# STM32H503 register map
File version: 0.3
CPU: CM33 r0p0, little endian, MPU, FPU, 4 interrupt priority bits
Registers are 32-bit, read-write, reset 0x0 unless marked. A register's access mark holds for its fields unless they carry their own. Offsets are from the block's base; [hi:lo] are bit positions; {n}, {i} and the like mark numbered series.

## EXTI — Extended interrupt/event controller
Base 0x44022000
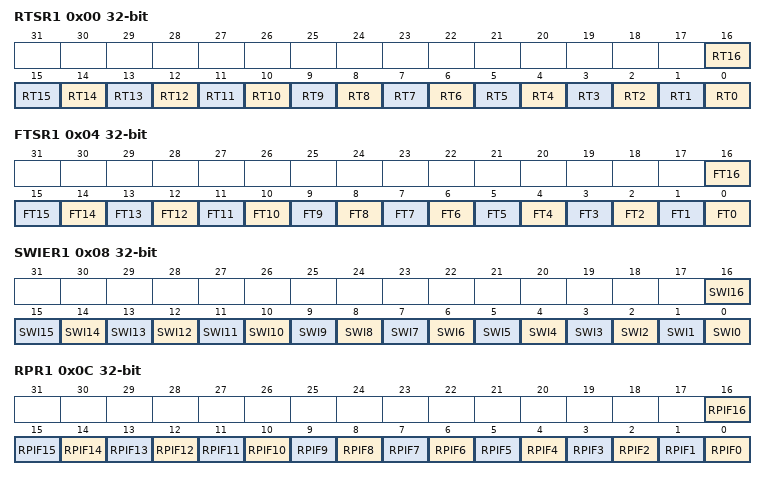
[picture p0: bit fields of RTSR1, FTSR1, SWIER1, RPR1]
0x00 RTSR1 — EXTI rising trigger selection register
  [n] RT{n} (n=0..16) — Rising trigger event configuration bit of configurable event input x (x = 16 to 0) When EXTI_PRIVCFGR.PRIVx is disabled, RTx can be accessed with unprivileged and privileged access. When EXTI_PRIVCFGR.PRIVx is enabled, RTx can only be accessed with privileged access. Unprivileged write to this bit x is discarded, unprivileged read returns 0.
0x04 FTSR1 — EXTI falling trigger selection register
  [n] FT{n} (n=0..16) — Falling trigger event configuration bit of configurable event input x (x = 16 to 0) When EXTI_PRIVCFGR.PRIVx is disabled, FTx can be accessed with unprivileged and privileged access. When EXTI_PRIVCFGR.PRIVx is enabled, FTx can only be accessed with privileged access. Unprivileged write to this FTx is discarded, unprivileged read returns 0.
0x08 SWIER1 — EXTI software interrupt event register
  [n] SWI{n} (n=0..16) — Software interrupt on event x (x = 16 to 0) When EXTI_PRIVCFGR.PRIVx is disabled, SWIx can be accessed with unprivileged and privileged access. When EXTI_PRIVCFGR.PRIVx is enabled, SWIx can only be accessed with privileged access. Unprivileged write to this SWIx is discarded, unprivileged read returns 0. A software interrupt is generated independent from the setting in EXTI_RTSR and EXTI_FTSR. It always returns 0 when read.
0x0C RPR1 — EXTI rising edge pending register
  [n] RPIF{n} (n=0..16) — configurable event inputs x rising edge pending bit (x = 16 to 0) When EXTI_PRIVCFGR.PRIVx is disabled, RPIFx can be accessed with unprivileged and privileged access. When EXTI_PRIVCFGR.PRIVx is enabled, RPIFx can only be accessed with privileged access. Unprivileged write to this RPIFx is discarded, unprivileged read returns 0. This bit is set when the rising edge event or an EXTI_SWIER software trigger arrives on the configurable event line. This bit is cleared by writing 1 to it.
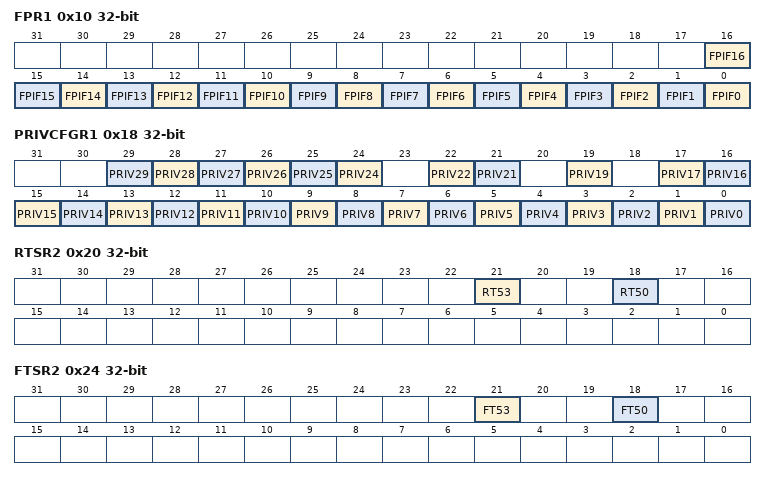
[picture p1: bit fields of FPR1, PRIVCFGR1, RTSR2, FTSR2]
0x10 FPR1 — EXTI falling edge pending register
  [n] FPIF{n} (n=0..16) — configurable event inputs x falling edge pending bit (x = 16 to 0) When EXTI_PRIVCFGR.PRIVx is disabled, FPIFx can be accessed with unprivileged and privileged access. When EXTI_PRIVCFGR.PRIVx is enabled, FPIFx can only be accessed with privileged access. Unprivileged write to this FPIFx is discarded, unprivileged read returns 0. This bit is set when the falling edge event arrives on the configurable event line. This bit is cleared by writing 1 to it.
0x18 PRIVCFGR1 — EXTI privilege configuration register
  [n] PRIV{n} (n=24..29) — Privilege enable on event input x (x = 29 to 24)
  [22] PRIV22 — Privilege enable on event input x (x = 22 to 21)
  [21] PRIV21 — Privilege enable on event input x (x = 22 to 21)
  [19] PRIV19 — Privilege enable on event input 19
  [n] PRIV{n} (n=0..17) — Privilege enable on event input x (x = 17 to 0)
0x20 RTSR2 — EXTI rising trigger selection register 2
  [21] RT53 — Rising trigger event configuration bit of configurable event input x When EXTI_PRIVCFGR.PRIVx is disabled, RTx can be accessed with unprivileged and privileged access. When EXTI_PRIVCFGR.PRIVx is enabled, RTx can only be accessed with privileged access. Unprivileged write to this bit x is discarded, unprivileged read returns 0.
  [18] RT50 — Rising trigger event configuration bit of configurable event input x When EXTI_PRIVCFGR.PRIVx is disabled, RTx can be accessed with unprivileged and privileged access. When EXTI_PRIVCFGR.PRIVx is enabled, RTx can only be accessed with privileged access. Unprivileged write to this bit x is discarded, unprivileged read returns 0.
0x24 FTSR2 — EXTI falling trigger selection register 2
  [21] FT53 — Falling trigger event configuration bit of configurable event input x When EXTI_PRIVCFGR.PRIVx is disabled, FTx can be accessed with unprivileged and privileged access. When EXTI_PRIVCFGR.PRIVx is enabled, FTx can only be accessed with privileged access. Unprivileged write to this FTx is discarded, unprivileged read returns 0.
  [18] FT50 — Falling trigger event configuration bit of configurable event input x When EXTI_PRIVCFGR.PRIVx is disabled, FTx can be accessed with unprivileged and privileged access. When EXTI_PRIVCFGR.PRIVx is enabled, FTx can only be accessed with privileged access. Unprivileged write to this FTx is discarded, unprivileged read returns 0.
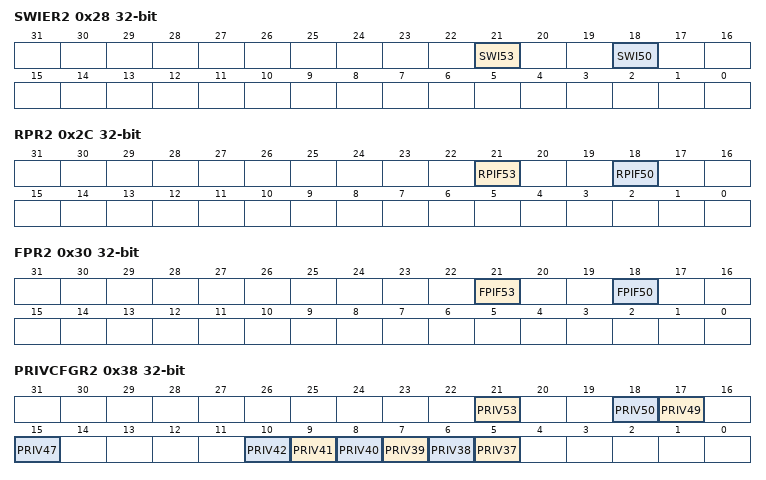
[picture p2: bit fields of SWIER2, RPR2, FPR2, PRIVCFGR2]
0x28 SWIER2 — EXTI software interrupt event register 2
  [21] SWI53 — Software interrupt on event x When EXTI_PRIVCFGR.PRIVx is disabled, SWIx can be accessed with unprivileged and privileged access. When EXTI_PRIVCFGR.PRIVx is enabled, SWIx can only be accessed with privileged access. Unprivileged write to this SWIx is discarded, unprivileged read returns 0. A software interrupt is generated independent from the setting in EXTI_RTSR and EXTI_FTSR. It always returns 0 when read.
  [18] SWI50 — Software interrupt on event x When EXTI_PRIVCFGR.PRIVx is disabled, SWIx can be accessed with unprivileged and privileged access. When EXTI_PRIVCFGR.PRIVx is enabled, SWIx can only be accessed with privileged access. Unprivileged write to this SWIx is discarded, unprivileged read returns 0. A software interrupt is generated independent from the setting in EXTI_RTSR and EXTI_FTSR. It always returns 0 when read.
0x2C RPR2 — EXTI rising edge pending register 2
  [21] RPIF53 — configurable event inputs x rising edge pending bit When EXTI_PRIVCFGR.PRIVx is disabled, RPIFx can be accessed with unprivileged and privileged access. When EXTI_PRIVCFGR.PRIVx is enabled, RPIFx can only be accessed with privileged access. Unprivileged write to this RPIFx is discarded, unprivileged read returns 0. This bit is set when the rising edge event or an EXTI_SWIER software trigger arrives on the configurable event line. This bit is cleared by writing 1 to it.
  [18] RPIF50 — configurable event inputs x rising edge pending bit When EXTI_PRIVCFGR.PRIVx is disabled, RPIFx can be accessed with unprivileged and privileged access. When EXTI_PRIVCFGR.PRIVx is enabled, RPIFx can only be accessed with privileged access. Unprivileged write to this RPIFx is discarded, unprivileged read returns 0. This bit is set when the rising edge event or an EXTI_SWIER software trigger arrives on the configurable event line. This bit is cleared by writing 1 to it.
0x30 FPR2 — EXTI falling edge pending register 2
  [21] FPIF53 — configurable event inputs x falling edge pending bit When EXTI_PRIVCFGR.PRIVx is disabled, FPIFx can be accessed with unprivileged and privileged access. When EXTI_PRIVCFGR.PRIVx is enabled, FPIFx can only be accessed with privileged access. Unprivileged write to this FPIFx is discarded, unprivileged read returns 0. This bit is set when the falling edge event arrives on the configurable event line. This bit is cleared by writing 1 to it.
  [18] FPIF50 — configurable event inputs x falling edge pending bit When EXTI_PRIVCFGR.PRIVx is disabled, FPIFx can be accessed with unprivileged and privileged access. When EXTI_PRIVCFGR.PRIVx is enabled, FPIFx can only be accessed with privileged access. Unprivileged write to this FPIFx is discarded, unprivileged read returns 0. This bit is set when the falling edge event arrives on the configurable event line. This bit is cleared by writing 1 to it.
0x38 PRIVCFGR2 — EXTI privilege configuration register 2
  [21] PRIV53 — Privilege enable on event input x
  [18] PRIV50 — Privilege enable on event input x (x = 50 to 49)
  [17] PRIV49 — Privilege enable on event input x (x = 50 to 49)
  [15] PRIV47 — Privilege enable on event input x
  [n-32] PRIV{n} (n=37..42) — Privilege enable on event input x (x = 42 to 37)
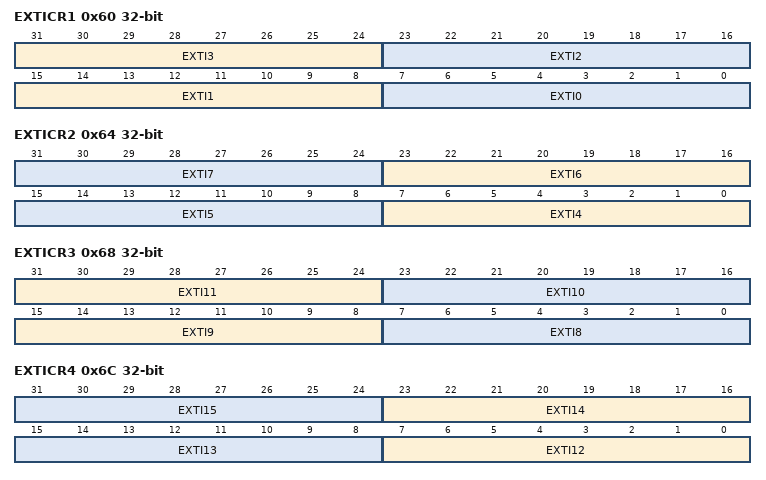
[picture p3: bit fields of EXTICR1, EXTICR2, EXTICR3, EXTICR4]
0x60 EXTICR1 — EXTI external interrupt selection register
  [31:24] EXTI3 — EXTI3 GPIO port selectio These bits are written by software to select the source input for EXTI3 external interrupt. When EXTI_PRIVCFGR.PRIV3 is disabled, EXTI3 can be accessed with privileged and unprivileged access. When EXTI_PRIVCFGR.PRIV3 is enabled, EXTI3 can only be accessed with privileged access. Unprivileged write to this bit is discarded. Others: reserved
  [23:16] EXTI2 — EXTI2 GPIO port selection These bits are written by software to select the source input for EXTI2 external interrupt. When EXTI_PRIVCFGR.PRIV2 is disabled, EXTI2 can be accessed with privileged and unprivileged access. When EXTI_PRIVCFGR.PRIV2 is enabled, EXTI2 can only be accessed with privileged access. Unprivileged write to this bit is discarded. Others: reserved
  [15:8] EXTI1 — EXTI1 GPIO port selection These bits are written by software to select the source input for EXTI1 external interrupt. When EXTI_PRIVCFGR.PRIV1 is disabled, EXTI1 can be accessed with privileged and unprivileged access. When EXTI_PRIVCFGR.PRIV1 is enabled, EXTI1 can only be accessed with privileged access. Unprivileged write to this bit is discarded. Others: reserved
  [7:0] EXTI0 — EXTI0 GPIO port selection These bits are written by software to select the source input for EXTI0 external interrupt. When EXTI_PRIVCFGR.PRIV0 is disabled, EXTI0 can be accessed with privileged and unprivileged access. When EXTI_PRIVCFGR.PRIV0 is enabled, EXTI0 can only be accessed with privileged access. Unprivileged write to this bit is discarded. Others: reserved
0x64 EXTICR2 — EXTI external interrupt selection register
  [8n-25:8n-32] EXTI{n} (n=4..7) — EXTI{n} GPIO port selection These bits are written by software to select the source input for EXTI{n} external interrupt. When EXTI_PRIVCFGR.PRIV{n} is disabled, EXTI{n} can be accessed with privileged and unprivileged access. When EXTI_PRIVCFGR.PRIV{n} is enabled, EXTI{n} can only be accessed with privileged access. Unprivileged write to this bit is discarded. Others: reserved
0x68 EXTICR3 — EXTI external interrupt selection register
  [31:24] EXTI11 — EXTI11 GPIO port selection These bits are written by software to select the source input for EXTI11 external interrupt. When EXTI_PRIVCFGR.PRIV11 is disabled, EXTI11 can be accessed with privileged and unprivileged access. When EXTI_PRIVCFGR.PRIV11 is enabled, EXTI11 can only be accessed with privileged access. Unprivileged write to this bit is discarded. Others: reserved
  [23:16] EXTI10 — EXTI10 GPIO port selection These bits are written by software to select the source input for EXTI10 external interrupt. When EXTI_PRIVCFGR.PRIV10 is disabled, EXTI10 can be accessed with privileged and unprivileged access. When EXTI_PRIVCFGR.PRIV10 is enabled, EXTI10 can only be accessed with privileged access. Unprivileged write to this bit is discarded. Others: reserved
  [15:8] EXTI9 — EXTI9 GPIO port selection These bits are written by software to select the source input for EXTI9 external interrupt. When EXTI_PRIVCFGR.PRIV9 is disabled, EXTI9 can be accessed with privileged and unprivileged access. When EXTI_PRIVCFGR.PRIV9 is enabled, EXTI9 can only be accessed with privileged access. Unprivileged write to this bit is discarded. Others: reserved
  [7:0] EXTI8 — EXTI8 GPIO port selection These bits are written by software to select the source input for EXTIm external interrupt. When EXTI_PRIVCFGR.PRIV8 is disabled, EXTI8 can be accessed with privileged and unprivileged access. When EXTI_PRIVCFGR.PRIV8 is enabled, EXTI8 can only be accessed with privileged access. Unprivileged write to this bit is discarded. Others: reserved
0x6C EXTICR4 — EXTI external interrupt selection register
  [8n-89:8n-96] EXTI{n} (n=12..15) — EXTI{n} GPIO port selection These bits are written by software to select the source input for EXTI{n} external interrupt. When EXTI_PRIVCFGR.PRIV{n} is disabled, EXTI{n} can be accessed with privileged and unprivileged access. When EXTI_PRIVCFGR.PRIV{n} is enabled, EXTI{n} can only be accessed with privileged access. Unprivileged write to this bit is discarded. Others: reserved
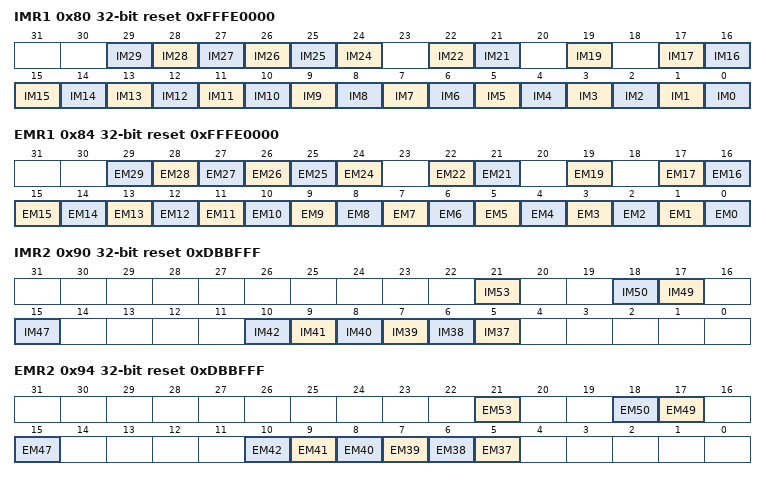
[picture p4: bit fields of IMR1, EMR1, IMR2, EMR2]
0x80 IMR1 reset 0xFFFE0000 — EXTI CPU wakeup with interrupt mask register
  [n] IM{n} (n=24..29) — CPU wakeup with interrupt mask on event input x (x = 29 to 24) When EXTI_PRIVCFGR.PRIVx is disabled, IMx can be accessed with privileged and unprivileged access. When EXTI_PRIVCFGR.PRIVx is enabled, IMx can only be accessed with privileged access. Unprivileged write to this bit is discarded.
  [22] IM22 — CPU wakeup with interrupt mask on event input x (x = 22 to 21) When EXTI_PRIVCFGR.PRIVx is disabled, IMx can be accessed with privileged and unprivileged access. When EXTI_PRIVCFGR.PRIVx is enabled, IMx can only be accessed with privileged access. Unprivileged write to this bit is discarded.
  [21] IM21 — CPU wakeup with interrupt mask on event input x (x = 22 to 21) When EXTI_PRIVCFGR.PRIVx is disabled, IMx can be accessed with privileged and unprivileged access. When EXTI_PRIVCFGR.PRIVx is enabled, IMx can only be accessed with privileged access. Unprivileged write to this bit is discarded.
  [19] IM19 — CPU wakeup with interrupt mask on event input x When EXTI_PRIVCFGR.PRIVx is disabled, IMx can be accessed with privileged and unprivileged access. When EXTI_PRIVCFGR.PRIVx is enabled, IMx can only be accessed with privileged access. Unprivileged write to this bit is discarded.
  [n] IM{n} (n=0..17) — CPU wakeup with interrupt mask on event input x (x = 17 to 0) When EXTI_PRIVCFGR.PRIVx is disabled, IMx can be accessed with privileged and unprivileged access. When EXTI_PRIVCFGR.PRIVx is enabled, IMx can only be accessed with privileged access. Unprivileged write to this bit is discarded.
0x84 EMR1 reset 0xFFFE0000 — EXTI CPU wakeup with event mask register
  [n] EM{n} (n=24..29) — CPU wakeup with event generation mask on event input x (x = 29 to 24) When EXTI_PRIVCFGR.PRIVx is disabled, EMx can be accessed with privileged and unprivileged access. When EXTI_PRIVCFGR.PRIVx is enabled, EMx can only be accessed with privileged access. Unprivileged write to this bit is discarded.
  [22] EM22 — CPU wakeup with event generation mask on event input x (x = 22 to 21) When EXTI_PRIVCFGR.PRIVx is disabled, EMx can be accessed with privileged and unprivileged access. When EXTI_PRIVCFGR.PRIVx is enabled, EMx can only be accessed with privileged access. Unprivileged write to this bit is discarded.
  [21] EM21 — CPU wakeup with event generation mask on event input x (x = 22 to 21) When EXTI_PRIVCFGR.PRIVx is disabled, EMx can be accessed with privileged and unprivileged access. When EXTI_PRIVCFGR.PRIVx is enabled, EMx can only be accessed with privileged access. Unprivileged write to this bit is discarded.
  [19] EM19 — CPU wakeup with event generation mask on event input x When EXTI_PRIVCFGR.PRIVx is disabled, EMx can be accessed with privileged and unprivileged access. When EXTI_PRIVCFGR.PRIVx is enabled, EMx can only be accessed with privileged access. Unprivileged write to this bit is discarded.
  [n] EM{n} (n=0..17) — CPU wakeup with event generation mask on event input x (x = 17 to 0) When EXTI_PRIVCFGR.PRIVx is disabled, EMx can be accessed with privileged and unprivileged access. When EXTI_PRIVCFGR.PRIVx is enabled, EMx can only be accessed with privileged access. Unprivileged write to this bit is discarded.
0x90 IMR2 reset 0xDBBFFF — EXTI CPU wakeup with interrupt mask register 2
  [21] IM53 — CPU wakeup with interrupt mask on event input x When EXTI_PRIVCFGR.PRIVx is disabled, IMx can be accessed with privileged and unprivileged access. When EXTI_PRIVCFGR.PRIVx is enabled, IMx can only be accessed with privileged access. Unprivileged write to this bit is discarded.
  [18] IM50 — CPU wakeup with interrupt mask on event input x (x = 50 to 49) When EXTI_PRIVCFGR.PRIVx is disabled, IMx can be accessed with privileged and unprivileged access. When EXTI_PRIVCFGR.PRIVx is enabled, IMx can only be accessed with privileged access. Unprivileged write to this bit is discarded.
  [17] IM49 — CPU wakeup with interrupt mask on event input x (x = 50 to 49) When EXTI_PRIVCFGR.PRIVx is disabled, IMx can be accessed with privileged and unprivileged access. When EXTI_PRIVCFGR.PRIVx is enabled, IMx can only be accessed with privileged access. Unprivileged write to this bit is discarded.
  [15] IM47 — CPU wakeup with interrupt mask on event input x When EXTI_PRIVCFGR.PRIVx is disabled, IMx can be accessed with privileged and unprivileged access. When EXTI_PRIVCFGR.PRIVx is enabled, IMx can only be accessed with privileged access. Unprivileged write to this bit is discarded.
  [n-32] IM{n} (n=37..42) — CPU wakeup with interrupt mask on event input x (x = 42 to 37) When EXTI_PRIVCFGR.PRIVx is disabled, IMx can be accessed with privileged and unprivileged access. When EXTI_PRIVCFGR.PRIVx is enabled, IMx can only be accessed with privileged access. Unprivileged write to this bit is discarded.
0x94 EMR2 reset 0xDBBFFF — EXTI CPU wakeup with event mask register 2
  [21] EM53 — CPU wakeup with event generation mask on event input x When EXTI_PRIVCFGR.PRIVx is disabled, EMx can be accessed with privileged and unprivileged access. When EXTI_PRIVCFGR.PRIVx is enabled, EMx can only be accessed with privileged access. Unprivileged write to this bit is discarded.
  [18] EM50 — CPU wakeup with event generation mask on event input x (x = 50 to 49) When EXTI_PRIVCFGR.PRIVx is disabled, EMx can be accessed with privileged and unprivileged access. When EXTI_PRIVCFGR.PRIVx is enabled, EMx can only be accessed with privileged access. Unprivileged write to this bit is discarded.
  [17] EM49 — CPU wakeup with event generation mask on event input x (x = 50 to 49) When EXTI_PRIVCFGR.PRIVx is disabled, EMx can be accessed with privileged and unprivileged access. When EXTI_PRIVCFGR.PRIVx is enabled, EMx can only be accessed with privileged access. Unprivileged write to this bit is discarded.
  [15] EM47 — CPU wakeup with event generation mask on event input x When EXTI_PRIVCFGR.PRIVx is disabled, EMx can be accessed with privileged and unprivileged access. When EXTI_PRIVCFGR.PRIVx is enabled, EMx can only be accessed with privileged access. Unprivileged write to this bit is discarded.
  [n-32] EM{n} (n=37..42) — CPU wakeup with event generation mask on event input x (x = 42 to 37) When EXTI_PRIVCFGR.PRIVx is disabled, EMx can be accessed with privileged and unprivileged access. When EXTI_PRIVCFGR.PRIVx is enabled, EMx can only be accessed with privileged access. Unprivileged write to this bit is discarded.
